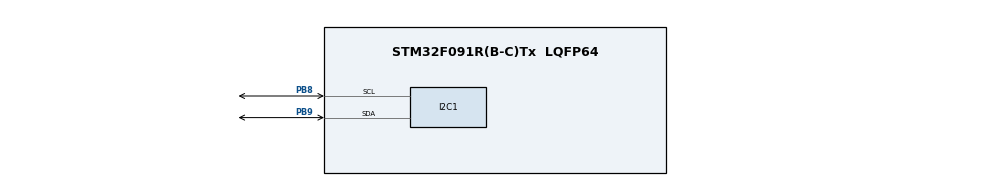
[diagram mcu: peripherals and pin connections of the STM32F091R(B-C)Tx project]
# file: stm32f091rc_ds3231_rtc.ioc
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I2C1.Timing=0x00201D2B
Mcu.Family=STM32F0
Mcu.Name=STM32F091R(B-C)Tx
Mcu.Package=LQFP64
PB8.Mode=I2C
PB8.Signal=I2C1_SCL
PB9.Mode=I2C
PB9.Signal=I2C1_SDA
ProjectManager.HeapSize=0x200
ProjectManager.StackSize=0x400
ProjectManager.TargetToolchain=CMake
board=custom

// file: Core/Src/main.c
/* USER CODE BEGIN Header */
/**
  ******************************************************************************
  * @file           : main.c
  * @brief          : Main program body
  ******************************************************************************
  * @attention
  *
  * Copyright (c) 2025 STMicroelectronics.
  * All rights reserved.
  *
  * This software is licensed under terms that can be found in the LICENSE file
  * in the root directory of this software component.
  * If no LICENSE file comes with this software, it is provided AS-IS.
  *
  ******************************************************************************
  */
/* USER CODE END Header */
#include "main.h"

/* USER CODE BEGIN Includes */
#include <stdio.h>
#include <string.h>

#include "lcd_i2c_driver.h"
#include "ds3231_rtc_driver.h"
/* USER CODE END Includes */

/* USER CODE BEGIN PD */
#define SET_RTC_TIME_ON_FIRST_RUN 0  // Set to 1 to set initial time, then back to 0
/* USER CODE END PD */

I2C_HandleTypeDef hi2c1;

void SystemClock_Config(void);
static void MX_GPIO_Init(void);
static void MX_I2C1_Init(void);
/* USER CODE BEGIN PFP */
RTC_Handle rtc;
LCD_Handle lcd;
/* USER CODE END PFP */

int main(void)
{

  /* MCU Configuration--------------------------------------------------------*/

  /* Reset of all peripherals, Initializes the Flash interface and the Systick. */
  HAL_Init();

  /* Configure the system clock */
  SystemClock_Config();

  /* Initialize all configured peripherals */
  MX_GPIO_Init();
  MX_I2C1_Init();
  /* USER CODE BEGIN 2 */

  // Initialize drivers
  LCD_Init(&lcd, &hi2c1);

  LCD_Clear(&lcd);
  LCD_PrintAt(&lcd, 0, 0, "  RTC DS3231 Test  ");
  LCD_DrawSeparator(&lcd, 1);

  // Initialize RTC
  if (RTC_Init(&rtc, &hi2c1) != HAL_OK) {
    LCD_PrintAt(&lcd, 2, 0, "RTC Init Failed!");
    LCD_PrintAt(&lcd, 3, 0, "Check connections");
    while(1) {
      HAL_Delay(1000);
    }
  }

  LCD_PrintAt(&lcd, 2, 0, "RTC Initialized!");
  HAL_Delay(1000);

  // Optional: Set initial time (comment out after first run)
  // Uncomment to set initial date/time:
#if SET_RTC_TIME_ON_FIRST_RUN
  RTC_DateTime init_time = {
      .seconds = 0,
      .minutes = 13,
      .hours = 01,        // 1:12 AM
      .day = 7,           // Friday
      .date = 8,          // 8th
      .month = 11,        // November
      .year = 2025
  };
  RTC_SetDateTime(&rtc, &init_time);
  LCD_PrintAt(&lcd, 2, 0, "Time Set!         ");
  HAL_Delay(1000);
#endif

  RTC_DateTime datetime;
  float rtc_temp;
  char buffer[21];
  uint32_t last_update = 0;

  LCD_Clear(&lcd);

  /* USER CODE END 2 */

  /* Infinite loop */
  /* USER CODE BEGIN WHILE */
  while (1)
  {
    // Update every second
    if (HAL_GetTick() - last_update >= 1000) {
      last_update = HAL_GetTick();

      // Read date and time
      if (RTC_GetDateTime(&rtc, &datetime) == HAL_OK) {
        // Display day and date
        LCD_PrintAt(&lcd, 0, 0, "                    ");
        snprintf(buffer, sizeof(buffer), "%s", RTC_GetDayName(datetime.day));
        LCD_PrintAt(&lcd, 0, 0, buffer);

        snprintf(buffer, sizeof(buffer), "%02d/%02d/%04d",
                 datetime.date, datetime.month, datetime.year);
        LCD_PrintAt(&lcd, 0, 20 - strlen(buffer), buffer);

        LCD_DrawSeparator(&lcd, 1);

        // Display time (large)
        snprintf(buffer, sizeof(buffer), "   %02d:%02d:%02d",
                 datetime.hours, datetime.minutes, datetime.seconds);
        LCD_PrintAt(&lcd, 2, 0, buffer);

        // Read temperature from RTC
        if (RTC_GetTemperature(&rtc, &rtc_temp) == HAL_OK) {
          snprintf(buffer, sizeof(buffer), "RTC Temp: %.2f", rtc_temp);
          LCD_PrintAt(&lcd, 3, 0, buffer);
          LCD_PrintCustomChar(&lcd, CHAR_DEGREE);
          LCD_Print(&lcd, "C  ");
        }
      } else {
        LCD_PrintAt(&lcd, 2, 0, "Error reading RTC!");
      }
    }

    HAL_Delay(10);
    /* USER CODE END WHILE */

  }
}

void SystemClock_Config(void)
{
  RCC_OscInitTypeDef RCC_OscInitStruct = {0};
  RCC_ClkInitTypeDef RCC_ClkInitStruct = {0};
  RCC_PeriphCLKInitTypeDef PeriphClkInit = {0};

  /** Initializes the RCC Oscillators according to the specified parameters
  * in the RCC_OscInitTypeDef structure.
  */
  RCC_OscInitStruct.OscillatorType = RCC_OSCILLATORTYPE_HSI;
  RCC_OscInitStruct.HSIState = RCC_HSI_ON;
  RCC_OscInitStruct.HSICalibrationValue = RCC_HSICALIBRATION_DEFAULT;
  RCC_OscInitStruct.PLL.PLLState = RCC_PLL_NONE;
  if (HAL_RCC_OscConfig(&RCC_OscInitStruct) != HAL_OK)
  {
    Error_Handler();
  }

  /** Initializes the CPU, AHB and APB buses clocks
  */
  RCC_ClkInitStruct.ClockType = RCC_CLOCKTYPE_HCLK|RCC_CLOCKTYPE_SYSCLK
                              |RCC_CLOCKTYPE_PCLK1;
  RCC_ClkInitStruct.SYSCLKSource = RCC_SYSCLKSOURCE_HSI;
  RCC_ClkInitStruct.AHBCLKDivider = RCC_SYSCLK_DIV1;
  RCC_ClkInitStruct.APB1CLKDivider = RCC_HCLK_DIV1;

  if (HAL_RCC_ClockConfig(&RCC_ClkInitStruct, FLASH_LATENCY_0) != HAL_OK)
  {
    Error_Handler();
  }
  PeriphClkInit.PeriphClockSelection = RCC_PERIPHCLK_I2C1;
  PeriphClkInit.I2c1ClockSelection = RCC_I2C1CLKSOURCE_HSI;
  if (HAL_RCCEx_PeriphCLKConfig(&PeriphClkInit) != HAL_OK)
  {
    Error_Handler();
  }
}

static void MX_I2C1_Init(void)
{

  hi2c1.Instance = I2C1;
  hi2c1.Init.Timing = 0x00201D2B;
  hi2c1.Init.OwnAddress1 = 0;
  hi2c1.Init.AddressingMode = I2C_ADDRESSINGMODE_7BIT;
  hi2c1.Init.DualAddressMode = I2C_DUALADDRESS_DISABLE;
  hi2c1.Init.OwnAddress2 = 0;
  hi2c1.Init.OwnAddress2Masks = I2C_OA2_NOMASK;
  hi2c1.Init.GeneralCallMode = I2C_GENERALCALL_DISABLE;
  hi2c1.Init.NoStretchMode = I2C_NOSTRETCH_DISABLE;
  if (HAL_I2C_Init(&hi2c1) != HAL_OK)
  {
    Error_Handler();
  }

  /** Configure Analogue filter
  */
  if (HAL_I2CEx_ConfigAnalogFilter(&hi2c1, I2C_ANALOGFILTER_ENABLE) != HAL_OK)
  {
    Error_Handler();
  }

  /** Configure Digital filter
  */
  if (HAL_I2CEx_ConfigDigitalFilter(&hi2c1, 0) != HAL_OK)
  {
    Error_Handler();
  }

}

static void MX_GPIO_Init(void)
{

  /* GPIO Ports Clock Enable */
  __HAL_RCC_GPIOB_CLK_ENABLE();

}

void Error_Handler(void)
{
  __disable_irq();
  while (1)
  {
  }
}
